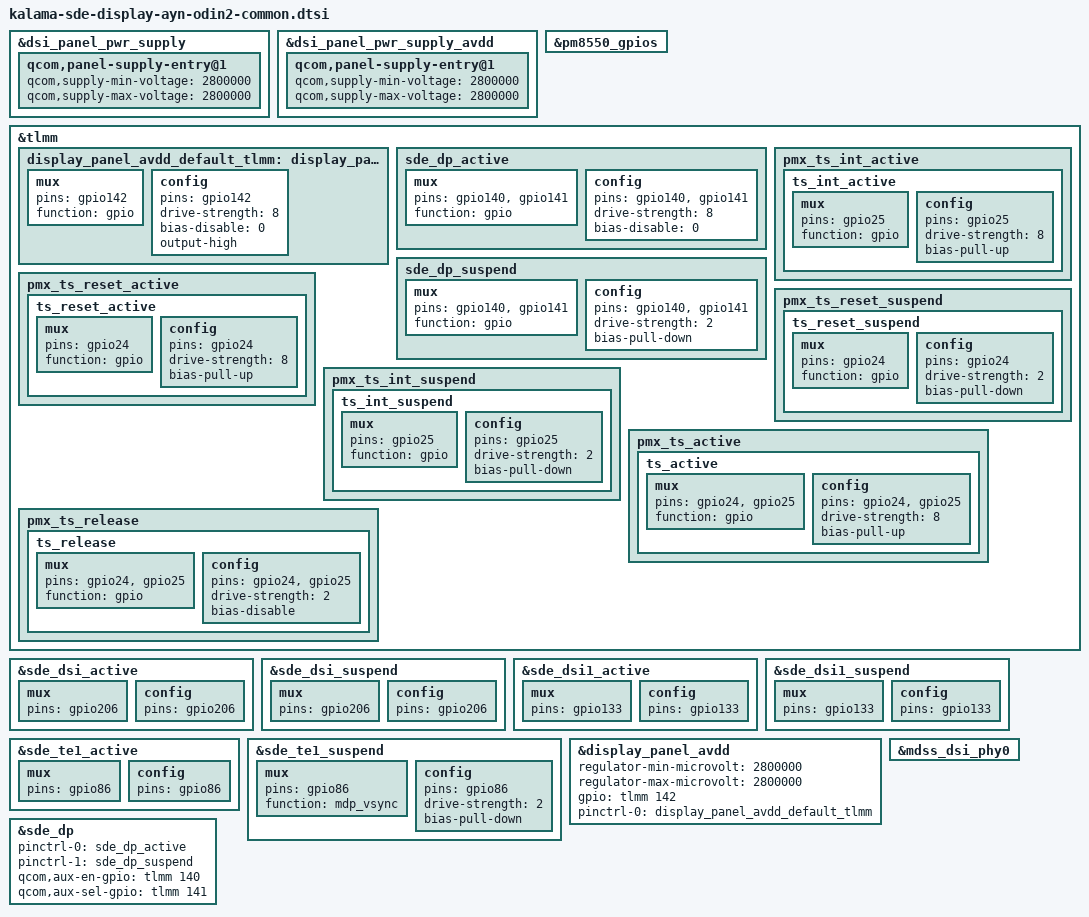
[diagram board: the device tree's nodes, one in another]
#include "../../../qcom/display/display/kalama-sde-display.dtsi"

&dsi_panel_pwr_supply {
	qcom,panel-supply-entry@1 {
		qcom,supply-min-voltage = <2800000>;
		qcom,supply-max-voltage = <2800000>;
	};
};

&dsi_panel_pwr_supply_avdd {
	qcom,panel-supply-entry@1 {
		qcom,supply-min-voltage = <2800000>;
		qcom,supply-max-voltage = <2800000>;
	};
};

&pm8550_gpios {
	/delete-node/ display_panel_avdd_default;
};

&tlmm {
	display_panel_avdd_default_tlmm: display_panel_avdd_default {
		mux {
			pins = "gpio142";
			function = "gpio";
		};
		config {
			pins = "gpio142";
			drive-strength = <8>;
			bias-disable = <0>;
			output-high;
		};
	};

	sde_dp_active: sde_dp_active {
		mux {
			pins = "gpio140","gpio141";
			function = "gpio";
		};

		config {
			pins = "gpio140","gpio141";
			drive-strength = <8>;   /* 8 mA */
			bias-disable = <0>;   /* no pull */
		};
	};

	sde_dp_suspend: sde_dp_suspend {
		mux {
			pins = "gpio140","gpio141";
			function = "gpio";
		};

		config {
			pins = "gpio140","gpio141";
			drive-strength = <2>;   /* 2 mA */
			bias-pull-down;         /* PULL DOWN */
		};
	};

	/* touchscreen pins */
	pmx_ts_int_active  {
		ts_int_active: ts_int_active {
			mux {
				pins = "gpio25";
				function = "gpio";
			};

			config {
				pins = "gpio25";
				drive-strength = <8>;
				bias-pull-up;
			};
		};
	};

	pmx_ts_reset_active {
			ts_reset_active: ts_reset_active {
				mux {
					pins = "gpio24";
					function = "gpio";
				};

				config {
					pins = "gpio24";
					drive-strength = <8>;
					bias-pull-up;
				};
			};
		};

	pmx_ts_reset_suspend {
		ts_reset_suspend: ts_reset_suspend {
			mux {
				pins = "gpio24";
				function = "gpio";
			};

			config {
				pins = "gpio24";
				drive-strength = <2>;
				bias-pull-down;
			};
		};
	};

	pmx_ts_int_suspend {
		ts_int_suspend: ts_int_suspend {
			mux {
				pins = "gpio25";
				function = "gpio";
			};

			config {
				pins = "gpio25";
				drive-strength = <2>;
				bias-pull-down;
			};
		};
	};

	pmx_ts_active {
		ts_active: ts_active {
			mux {
				pins = "gpio24", "gpio25";
				function = "gpio";
			};
			config {
				pins = "gpio24", "gpio25";
				drive-strength = <8>;
				bias-pull-up;
			};
		};
	};

	pmx_ts_release {
		ts_release: ts_release {
			mux {
				pins = "gpio24", "gpio25";
				function = "gpio";
			};

			config {
				pins = "gpio24", "gpio25";
				drive-strength = <2>;
				bias-disable;
			};
		};
	};
};

&sde_dsi_active {
	mux {
		pins = "gpio206";
	};

	config {
		pins = "gpio206";
	};
};

&sde_dsi_suspend {
	mux {
		pins = "gpio206";
	};

	config {
		pins = "gpio206";
	};
};

&sde_dsi1_active {
	mux {
		pins = "gpio133";
	};

	config {
		pins = "gpio133";
	};
};

&sde_dsi1_suspend {
	mux {
		pins = "gpio133";
	};

	config {
		pins = "gpio133";
	};
};

&sde_te1_active {
	mux {
		pins = "gpio86";
	};

	config {
		pins = "gpio86";
	};
};

&sde_te1_suspend {
	mux {
		pins = "gpio86";
		function = "mdp_vsync";
	};

	config {
		pins = "gpio86";
		drive-strength = <2>;   /* 2 mA */
		bias-pull-down;         /* PULL DOWN */
	};
};

&display_panel_avdd {
	regulator-min-microvolt = <2800000>;
	regulator-max-microvolt = <2800000>;
	gpio = <&tlmm 142 0>;
	pinctrl-0 = <&display_panel_avdd_default_tlmm>;
};

&sde_dp {
	pinctrl-names = "mdss_dp_active", "mdss_dp_sleep";
	pinctrl-0 = <&sde_dp_active>;
	pinctrl-1 = <&sde_dp_suspend>;

	/delete-property/ qcom,dp-aux-switch;
	qcom,aux-en-gpio = <&tlmm 140 0>;
	qcom,aux-sel-gpio = <&tlmm 141 0>;
};

&mdss_dsi_phy0 {
	/delete-property/ qcom,dsi-pll-ssc-en;
	/delete-property/ qcom,dsi-pll-ssc-mode;
};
